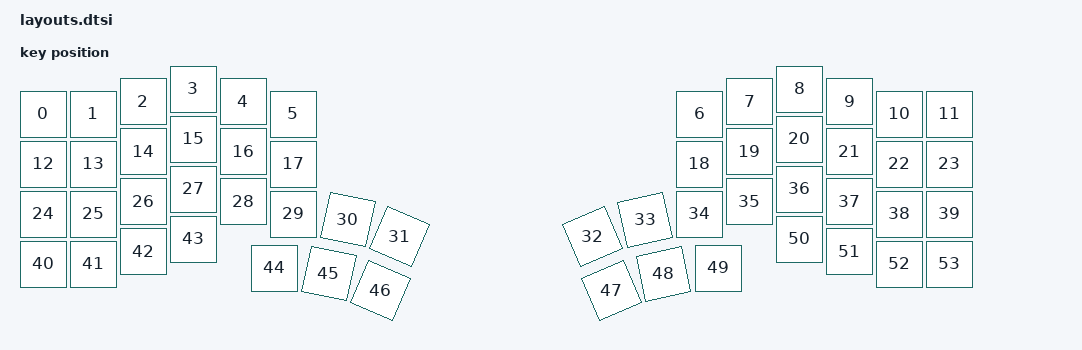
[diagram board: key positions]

#include <physical_layouts.dtsi>
/ {
    physical_layout0: physical_layout0 {
        compatible = "zmk,physical-layout";
        display-name = "Layout";
        keys
            = <&key_physical_attrs 100 100 0 100 0 0 0>
			,<&key_physical_attrs 100 100 100 100 0 0 0>
			,<&key_physical_attrs 100 100 200 75 0 0 0>
			,<&key_physical_attrs 100 100 300 50 0 0 0>
			,<&key_physical_attrs 100 100 400 75 0 0 0>
			,<&key_physical_attrs 100 100 500 100 0 0 0>
			,<&key_physical_attrs 100 100 1313 100 0 0 0>
			,<&key_physical_attrs 100 100 1413 75 0 0 0>
			,<&key_physical_attrs 100 100 1513 50 0 0 0>
			,<&key_physical_attrs 100 100 1613 75 0 0 0>
			,<&key_physical_attrs 100 100 1713 100 0 0 0>
			,<&key_physical_attrs 100 100 1813 100 0 0 0>
			,<&key_physical_attrs 100 100 0 200 0 0 0>
			,<&key_physical_attrs 100 100 100 200 0 0 0>
			,<&key_physical_attrs 100 100 200 175 0 0 0>
			,<&key_physical_attrs 100 100 300 150 0 0 0>
			,<&key_physical_attrs 100 100 400 175 0 0 0>
			,<&key_physical_attrs 100 100 500 200 0 0 0>
			,<&key_physical_attrs 100 100 1313 200 0 0 0>
			,<&key_physical_attrs 100 100 1413 175 0 0 0>
			,<&key_physical_attrs 100 100 1513 150 0 0 0>
			,<&key_physical_attrs 100 100 1613 175 0 0 0>
			,<&key_physical_attrs 100 100 1713 200 0 0 0>
			,<&key_physical_attrs 100 100 1813 200 0 0 0>
			,<&key_physical_attrs 100 100 0 300 0 0 0>
			,<&key_physical_attrs 100 100 100 300 0 0 0>
			,<&key_physical_attrs 100 100 200 275 0 0 0>
			,<&key_physical_attrs 100 100 300 250 0 0 0>
			,<&key_physical_attrs 100 100 400 275 0 0 0>
			,<&key_physical_attrs 100 100 500 300 0 0 0>
			,<&key_physical_attrs 100 100 621 302 1193 621 302>
			,<&key_physical_attrs 100 100 737 329 2300 737 329>
			,<&key_physical_attrs 100 100 1084 368 (-2300) 1084 368>
			,<&key_physical_attrs 100 100 1195 323 (-1193) 1195 323>
			,<&key_physical_attrs 100 100 1313 300 0 0 0>
			,<&key_physical_attrs 100 100 1413 275 0 0 0>
			,<&key_physical_attrs 100 100 1513 250 0 0 0>
			,<&key_physical_attrs 100 100 1613 275 0 0 0>
			,<&key_physical_attrs 100 100 1713 300 0 0 0>
			,<&key_physical_attrs 100 100 1813 300 0 0 0>
			,<&key_physical_attrs 100 100 0 400 0 0 0>
			,<&key_physical_attrs 100 100 100 400 0 0 0>
			,<&key_physical_attrs 100 100 200 375 0 0 0>
			,<&key_physical_attrs 100 100 300 350 0 0 0>
			,<&key_physical_attrs 100 100 462 408 0 0 0>
			,<&key_physical_attrs 100 100 583 410 1193 583 410>
			,<&key_physical_attrs 100 100 699 437 2300 699 437>
			,<&key_physical_attrs 100 100 1122 476 (-2300) 1122 476>
			,<&key_physical_attrs 100 100 1232 431 (-1193) 1232 431>
			,<&key_physical_attrs 100 100 1351 408 0 0 0>
			,<&key_physical_attrs 100 100 1513 350 0 0 0>
			,<&key_physical_attrs 100 100 1613 375 0 0 0>
			,<&key_physical_attrs 100 100 1713 400 0 0 0>
			,<&key_physical_attrs 100 100 1813 400 0 0 0>
            ;
    };
};
    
